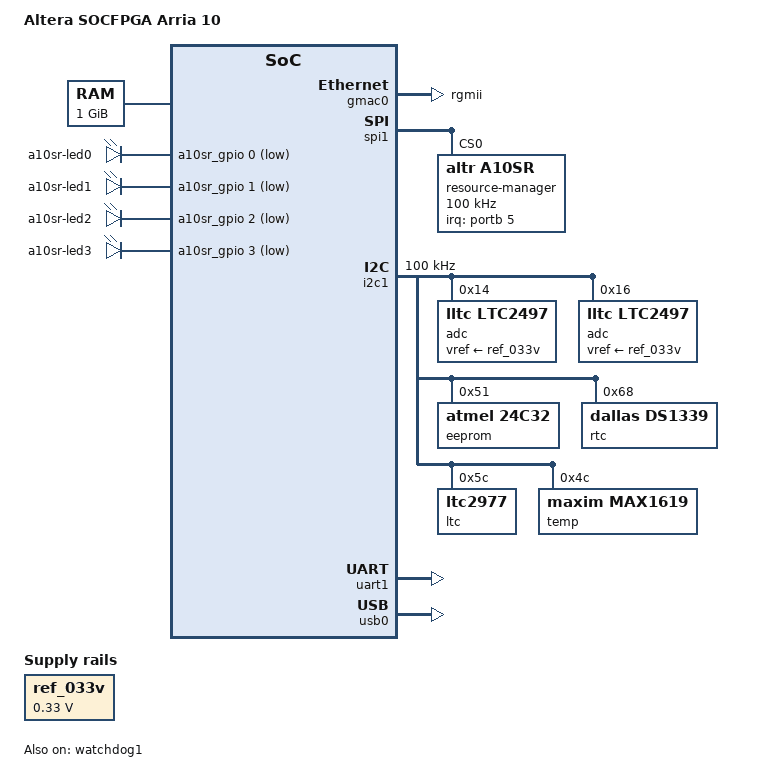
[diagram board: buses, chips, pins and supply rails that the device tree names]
#include "socfpga_arria10.dtsi"
/ {
	model = "Altera SOCFPGA Arria 10";
	compatible = "altr,socfpga-arria10-socdk", "altr,socfpga-arria10", "altr,socfpga";
	aliases {
		ethernet0 = &gmac0;
		serial0 = &uart1;
	};
	chosen {
		bootargs = "earlyprintk";
		stdout-path = "serial0:115200n8";
	};
	memory@0 {
		name = "memory";
		device_type = "memory";
		reg = <0x0 0x40000000>;  
	};
	a10leds {
		compatible = "gpio-leds";
		a10sr_led0 {
			label = "a10sr-led0";
			gpios = <&a10sr_gpio 0 1>;
		};
		a10sr_led1 {
			label = "a10sr-led1";
			gpios = <&a10sr_gpio 1 1>;
		};
		a10sr_led2 {
			label = "a10sr-led2";
			gpios = <&a10sr_gpio 2 1>;
		};
		a10sr_led3 {
			label = "a10sr-led3";
			gpios = <&a10sr_gpio 3 1>;
		};
	};
	ref_033v: 033-v-ref {
		compatible = "regulator-fixed";
		regulator-name = "0.33V";
		regulator-min-microvolt = <330000>;
		regulator-max-microvolt = <330000>;
	};
	soc {
		clkmgr@ffd04000 {
			clocks {
				osc1 {
					clock-frequency = <25000000>;
				};
			};
		};
	};
};
&gmac0 {
	phy-mode = "rgmii";
	phy-addr = <0xffffffff>;  
	txd0-skew-ps = <0>;  
	txd1-skew-ps = <0>;  
	txd2-skew-ps = <0>;  
	txd3-skew-ps = <0>;  
	rxd0-skew-ps = <420>;  
	rxd1-skew-ps = <420>;  
	rxd2-skew-ps = <420>;  
	rxd3-skew-ps = <420>;  
	txen-skew-ps = <0>;  
	txc-skew-ps = <1860>;  
	rxdv-skew-ps = <420>;  
	rxc-skew-ps = <1680>;  
	max-frame-size = <3800>;
	status = "okay";
};
&gpio1 {
	status = "okay";
};
&spi1 {
	status = "okay";
	resource-manager@0 {
		compatible = "altr,a10sr";
		reg = <0>;
		spi-max-frequency = <100000>;
		interrupt-parent = <&portb>;
		interrupts = <5 IRQ_TYPE_LEVEL_LOW>;
		interrupt-controller;
		#interrupt-cells = <2>;
		a10sr_gpio: gpio-controller {
			compatible = "altr,a10sr-gpio";
			gpio-controller;
			#gpio-cells = <2>;
		};
		a10sr_rst: reset-controller {
			compatible = "altr,a10sr-reset";
			#reset-cells = <1>;
		};
	};
};
&i2c1 {
	status = "okay";
	clock-frequency = <100000>;
	i2c-sda-falling-time-ns = <6000>;
	i2c-scl-falling-time-ns = <6000>;
	adc@14 {
		compatible = "lltc,ltc2497";
		reg = <0x14>;
		vref-supply = <&ref_033v>;
	};
	adc@16 {
		compatible = "lltc,ltc2497";
		reg = <0x16>;
		vref-supply = <&ref_033v>;
	};
	eeprom@51 {
		compatible = "atmel,24c32";
		reg = <0x51>;
		pagesize = <32>;
	};
	rtc@68 {
		compatible = "dallas,ds1339";
		reg = <0x68>;
	};
	ltc@5c {
		compatible = "ltc2977";
		reg = <0x5c>;
	};
	temp@4c {
		compatible = "maxim,max1619";
		reg = <0x4c>;
	};
};
&uart1 {
	status = "okay";
};
&usb0 {
	status = "okay";
	disable-over-current;
};
&watchdog1 {
	status = "okay";
};
